# psoc4200l register map
Vendor: Cypress Semiconductor; Series: PSoC4200L; File version: 1.0
CPU: CM0 r0p1, little endian, no MPU, no FPU, 2 interrupt priority bits
Registers are 32-bit, read-write, reset 0x0 unless marked. A register's access mark holds for its fields unless they carry their own. Offsets are from the block's base; [hi:lo] are bit positions; lines under a group give offsets from that group; {n}, {i} and the like mark numbered series; 'fields as' and 'values as' point back to an identical list; <NAME> marks a mode.

## LPCOMP — Low Power Comparators
Base 0x402B0000
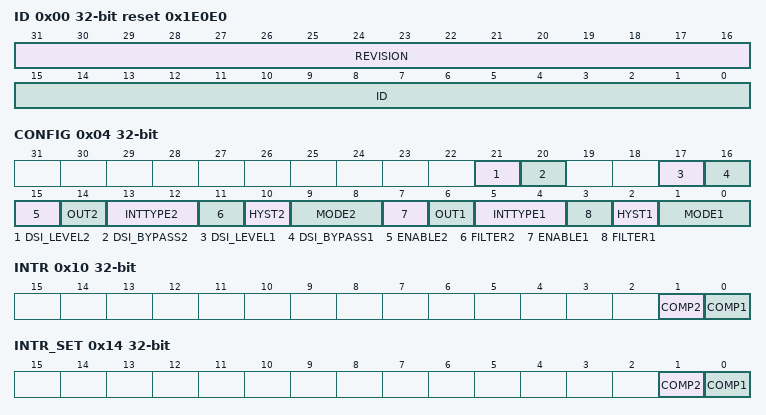
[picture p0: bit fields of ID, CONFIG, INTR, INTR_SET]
0x00 ID ro reset 0x1E0E0 — ID & Revision
  [31:16] REVISION — the version number is 0x0001
  [15:0] ID — the ID of LPCOMP peripheral is 0xE0E0
0x04 CONFIG — LPCOMP Configuration Register
  [21] DSI_LEVEL2 — Opamp2 comparator DSI (trigger) out level : 0=pulse, 1=level
  [20] DSI_BYPASS2 — Opamp2 bypass comparator output synchronization for DSI output: 0=synchronize (level or pulse), 1=bypass (output async) Note that in DeepSleep mode this bit needs to be set to observe the DSI output on the dedicated pin.
  [17] DSI_LEVEL1 — Opamp1 comparator DSI (trigger) out level : 0=pulse, 1=level
  [16] DSI_BYPASS1 — Opamp1 bypass comparator output synchronization for DSI output: 0=synchronize (level or pulse), 1=bypass (output async) Note that in DeepSleep mode this bit needs to be set to observe the DSI output on the dedicated pin.
  [15] ENABLE2 — Enable comparator #2
  [14] OUT2 ro — Current output value of the comparator.
  [13:12] INTTYPE2 — Sets which edge will trigger an IRQ
    0=DISABLE (Disabled, no interrupts will be detected); 1=RISING (Rising edge); 2=FALLING (Falling edge); 3=BOTH (Both rising and falling edges)
  [11] FILTER2
  [10] HYST2 — Add 10mV hysteresis to the comparator - 0: Enable Hysteresis - 1: Disable Hysteresis
  [9:8] MODE2 — Operating mode for the comparator
    0=SLOW (Slow operating mode (uses less power, <50uA)); 1=FAST (Fast operating mode (uses more power, <400uA)); 2=ULP (Ultra low power operting mode (uses ~2-4uA))
  [7] ENABLE1 — Enable comparator #1
  [6] OUT1 ro — Current output value of the comparator.
  [5:4] INTTYPE1 — Sets which edge will trigger an IRQ
    values as INTTYPE2
  [3] FILTER1
  [2] HYST1 — Add 10mV hysteresis to the comparator - 0: Enable Hysteresis - 1: Disable Hysteresis
  [1:0] MODE1 — Operating mode for the comparator
    values as MODE2
0x10 INTR — LPCOMP Interrupt request register
  [1] COMP2 — Comparator 2 Interrupt: hardware sets this interrupt when comparator 0 triggers. Write with '1' to clear bit.
  [0] COMP1 — Comparator 1 Interrupt: hardware sets this interrupt when comparator 0 triggers. Write with '1' to clear bit.
0x14 INTR_SET — LPCOMP Interrupt set register
  [1] COMP2 — Write with '1' to set corresponding bit in interrupt request register.
  [0] COMP1 — Write with '1' to set corresponding bit in interrupt request register.
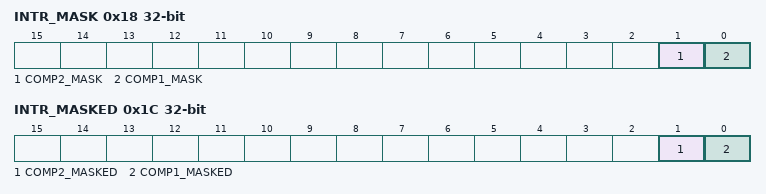
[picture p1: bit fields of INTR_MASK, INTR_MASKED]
0x18 INTR_MASK — LPCOMP Interrupt request mask
  [1] COMP2_MASK — Mask bit for corresponding bit in interrupt request register.
  [0] COMP1_MASK — Mask bit for corresponding bit in interrupt request register.
0x1C INTR_MASKED ro — LPCOMP Interrupt request masked
  [1] COMP2_MASKED — Logical and of corresponding request and mask bits.
  [0] COMP1_MASKED — Logical and of corresponding request and mask bits.
0xFF00 TRIM1 — LPCOMP Trim Register
  [4:0] COMP1_TRIMA — Trim A for Comparator #1
0xFF04 TRIM2 — LPCOMP Trim Register
  [4:0] COMP1_TRIMB — Trim B for Comparator #1
0xFF08 TRIM3 — LPCOMP Trim Register
  [4:0] COMP2_TRIMA — Trim A for Comparator #2
0xFF0C TRIM4 — LPCOMP Trim Register
  [4:0] COMP2_TRIMB — Trim B for Comparator #2

## PASS0 — PASS top-level MMIO (DSAB, INTR)
Base 0x403F0000
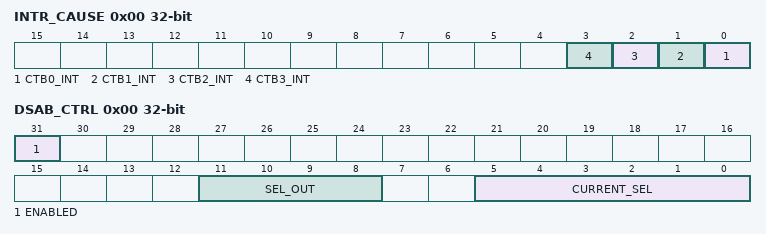
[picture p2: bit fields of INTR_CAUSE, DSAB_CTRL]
0x00 INTR_CAUSE ro — Interrupt cause register
  [n] CTB{n}_INT (n=0..3) — CTB{n} interrupt pending
0x30 DFT_CTRL — DFT control register
  [0] DSAB_ADFT_RES_EN — Close the switch to connect the DSAB ADFT resistor to the AMUXBUS
0xE00 DSAB group — DSAB configuration
  0x00 DSAB_CTRL — global DSAB control
    [31] ENABLED — - 0: DSAB IP disabled (put analog in power down, put all iref in bypass) - 1: DSAB IP enabled
    [11:8] SEL_OUT — selection for ibias_out<n> and irefout_ptat_2pt4<n> 0: bypass respectively irefin_0tc_2pt4<n> and bypass irefin_ptat_2pt4<n> 1: drive respectively replicated dsab_ibias<n> and 0.
    [5:0] CURRENT_SEL — current selection for dsab_ibias, dsab_ibias = CURRENT_SEL * 0.075 uA (+/-5 percent)
  0x04 DSAB_DFT — DFT bits
    [3:0] EN_DFT — - 0: DSAB DFT disabled - 1: DSAB DFT enabled (connect output to amuxbus)
0xF00 DSAB_TRIM — DSAB Trim bits
  [3:0] IBIAS_TRIM — 1111=lowest, 0000=highest
